# AT32UC3B1512 device description
Architecture: AVR32_UC3; Family: AVR UC3
Registers are 32-bit, read-write, reset 0x0 unless marked. A register's access mark holds for its fields unless they carry their own. Offsets are from the block's base; [hi:lo] are bit positions; {n}, {i} and the like mark numbered series.

## USART — Universal Synchronous/Asynchronous Receiver/Transmitter
Instances: USART0 0xffff1400, USART1 0xffff1800, USART2 0xffff1c00
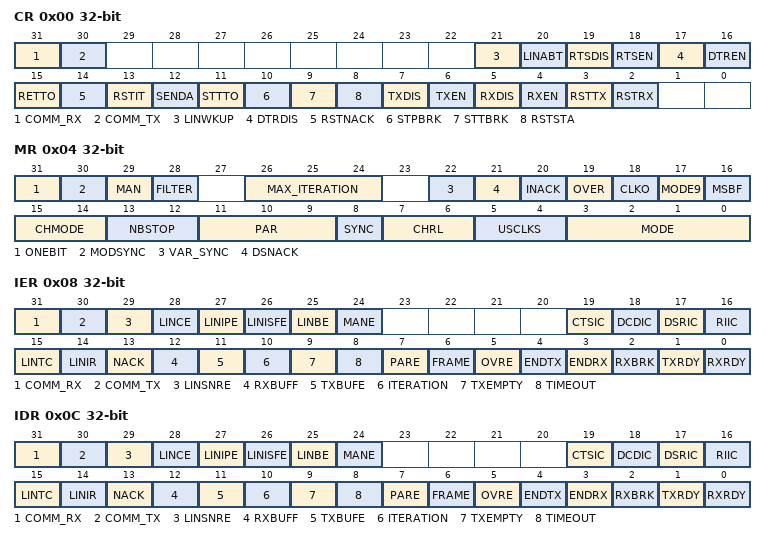
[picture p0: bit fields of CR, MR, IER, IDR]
0x00 CR wo reset not defined — Control Register
  [31] COMM_RX — Disable COMM_RX (from ARM) Interrupt
  [30] COMM_TX — Disable COMM_TX (from ARM) Interrupt
  [21] LINWKUP — Sends a wakeup signal on the LIN bus
  [20] LINABT — Abort the current LIN transmission
  [19] RTSDIS — Request to Send Disable
  [18] RTSEN — Request to Send Enable
  [17] DTRDIS — Data Terminal Ready Disable
  [16] DTREN — Data Terminal Ready Enable
  [15] RETTO — Rearm Time-out
  [14] RSTNACK — Reset Non Acknowledge
  [13] RSTIT — Reset Iterations
  [12] SENDA — Send Address
  [11] STTTO — Start Time-out
  [10] STPBRK — Stop Break
  [9] STTBRK — Start Break
  [8] RSTSTA — Reset Status Bits
  [7] TXDIS — Transmitter Disable
  [6] TXEN — Transmitter Enable
  [5] RXDIS — Receiver Disable
  [4] RXEN — Receiver Enable
  [3] RSTTX — Reset Transmitter
  [2] RSTRX — Reset Receiver
0x04 MR — Mode Register
  [31] ONEBIT — Start Frame Delimiter selector
  [30] MODSYNC — Manchester Synchronization Mode
  [29] MAN — Manchester Encoder/Decoder Enable
  [28] FILTER — Infrared Receive Line Filter
  [26:24] MAX_ITERATION — Max interation
  [22] VAR_SYNC — Variable synchronization of command/data sync Start Frame Delimiter
  [21] DSNACK — Disable Successive NACK
  [20] INACK — Inhibit Non Acknowledge
  [19] OVER — Oversampling Mode
    0=X16; 1=X8
  [18] CLKO — Clock Output Select
  [17] MODE9 — 9-bit Character Length
  [16] MSBF — Bit Order
    0=LSBF; 1=MSBF
  [15:14] CHMODE — Channel Mode
    0=NORMAL; 1=ECHO; 2=LOCAL_LOOP; 3=REMOTE_LOOP
  [13:12] NBSTOP — Number of Stop Bits
    0=1; 1=1_5; 2=2
  [11:9] PAR — Parity Type
    0=EVEN; 1=ODD; 2=SPACE; 3=MARK; 4=NONE; 6=MULTI
  [8] SYNC — Synchronous Mode Select
  [7:6] CHRL — Character Length.
    {v}={v+5} (v=0..3)
  [5:4] USCLKS — Clock Selection
    0=MCK; 1=MCK_DIV; 3=SCK
  [3:0] MODE — Usart Mode
    0=NORMAL; 1=RS485; 2=HARDWARE; 3=MODEM; 4=ISO7816_T0; 6=ISO7816_T1; 8=IRDA; 10=LIN_Master; 11=LIN_Slave; 14=SPI_Master; 15=SPI_Slave
0x08 IER wo — Interrupt Enable Register
  [31] COMM_RX — Enable COMM_RX (from ARM) Interrupt
  [30] COMM_TX — Enable COMM_TX (from ARM) Interrupt
  [29] LINSNRE — LIN Slave Not Responding Error Interrupt Enable
  [28] LINCE — LIN Checksum Error Interrupt Enable
  [27] LINIPE — LIN Identifier Parity Interrupt Enable
  [26] LINISFE — LIN Inconsistent Synch Field Error Interrupt Enable
  [25] LINBE — LIN Bus Error Interrupt Enable
  [24] MANE — Manchester Error Interrupt Enable
  [19] CTSIC — Clear to Send Input Change Interrupt Enable
  [18] DCDIC — Data Carrier Detect Input Change Interrupt Enable
  [17] DSRIC — Data Set Ready Input Change Enable
  [16] RIIC — Ring Indicator Input Change Enable
  [15] LINTC — LIN Transfer Conpleted Interrupt Enable
  [14] LINIR — LIN Identifier Received Interrupt Enable
  [13] NACK — Non Acknowledge Interrupt Enable
  [12] RXBUFF — Buffer Full Interrupt Enable
  [11] TXBUFE — Buffer Empty Interrupt Enable
  [10] ITERATION — Iteration Interrupt Enable
  [9] TXEMPTY — Transmitter Empty Interrupt Enable
  [8] TIMEOUT — Time-out Interrupt Enable
  [7] PARE — Parity Error Interrupt Enable
  [6] FRAME — Framing Error Interrupt Enable
  [5] OVRE — Overrun Error Interrupt Enable
  [4] ENDTX — End of Transmit Interrupt Enable
  [3] ENDRX — End of Receive Transfer Interrupt Enable
  [2] RXBRK — Receiver Break Interrupt Enable
  [1] TXRDY — Transmitter Ready Interrupt Enable
  [0] RXRDY — Receiver Ready Interrupt Enable
0x0C IDR wo — Interrupt Disable Register
  [31] COMM_RX — Disable COMM_RX (from ARM) Interrupt
  [30] COMM_TX — Disable COMM_TX (from ARM) Interrupt
  [29] LINSNRE — LIN Slave Not Responding Error Interrupt Disable
  [28] LINCE — LIN Checksum Error Interrupt Disable
  [27] LINIPE — LIN Identifier Parity Interrupt Disable
  [26] LINISFE — LIN Inconsistent Synch Field Error Interrupt Disable
  [25] LINBE — LIN Bus Error Interrupt Disable
  [24] MANE — Manchester Error Interrupt Disable
  [19] CTSIC — Clear to Send Input Change Interrupt Disable
  [18] DCDIC — Data Carrier Detect Input Change Interrupt Disable
  [17] DSRIC — Data Set Ready Input Change Disable
  [16] RIIC — Ring Indicator Input Change Disable
  [15] LINTC — LIN Transfer Conpleted Interrupt Disable
  [14] LINIR — LIN Identifier Received Interrupt Disable
  [13] NACK — Non Acknowledge Interrupt Disable
  [12] RXBUFF — Buffer Full Interrupt Disable
  [11] TXBUFE — Buffer Empty Interrupt Disable
  [10] ITERATION — Iteration Interrupt Disable
  [9] TXEMPTY — Transmitter Empty Interrupt Disable
  [8] TIMEOUT — Time-out Interrupt Disable
  [7] PARE — Parity Error Interrupt Disable
  [6] FRAME — Framing Error Interrupt Disable
  [5] OVRE — Overrun Error Interrupt Disable
  [4] ENDTX — End of Transmit Interrupt Disable
  [3] ENDRX — End of Receive Transfer Interrupt Disable
  [2] RXBRK — Receiver Break Interrupt Disable
  [1] TXRDY — Transmitter Ready Interrupt Disable
  [0] RXRDY — Receiver Ready Interrupt Disable
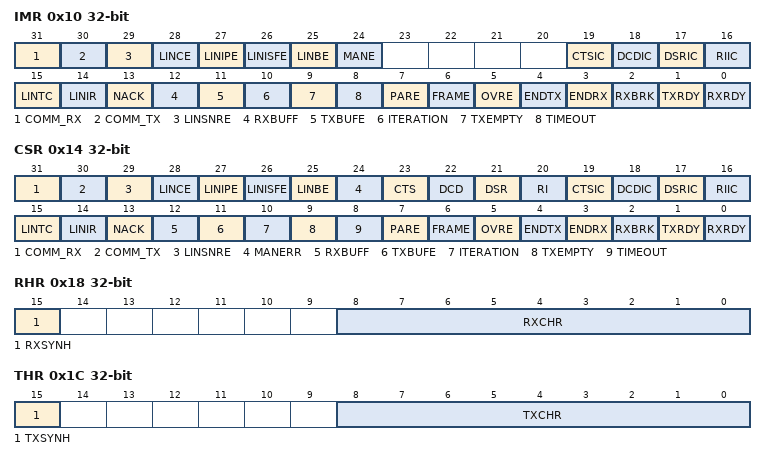
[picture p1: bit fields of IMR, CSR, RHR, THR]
0x10 IMR ro — Interrupt Mask Register
  [31] COMM_RX — Mask COMM_RX (from ARM) Interrupt
  [30] COMM_TX — Mask COMM_TX (from ARM) Interrupt
  [29] LINSNRE — LIN Slave Not Responding Error Interrupt Mask
  [28] LINCE — LIN Checksum Error Interrupt Mask
  [27] LINIPE — LIN Identifier Parity Interrupt Mask
  [26] LINISFE — LIN Inconsistent Synch Field Error Interrupt Mask
  [25] LINBE — LIN Bus Error Interrupt Mask
  [24] MANE — Manchester Error Interrupt Mask
  [19] CTSIC — Clear to Send Input Change Interrupt Mask
  [18] DCDIC — Data Carrier Detect Input Change Interrupt Mask
  [17] DSRIC — Data Set Ready Input Change Mask
  [16] RIIC — Ring Indicator Input Change Mask
  [15] LINTC — LIN Transfer Conpleted Interrupt Mask
  [14] LINIR — LIN Identifier Received Interrupt Mask
  [13] NACK — Non Acknowledge Interrupt Mask
  [12] RXBUFF — Buffer Full Interrupt Mask
  [11] TXBUFE — Buffer Empty Interrupt Mask
  [10] ITERATION — Iteration Interrupt Mask
  [9] TXEMPTY — TXEMPTY Interrupt Mask
  [8] TIMEOUT — Time-out Interrupt Mask
  [7] PARE — Parity Error Interrupt Mask
  [6] FRAME — Framing Error Interrupt Mask
  [5] OVRE — Overrun Error Interrupt Mask
  [4] ENDTX — End of Transmit Interrupt Mask
  [3] ENDRX — End of Receive Transfer Interrupt Mask
  [2] RXBRK — Receiver Break Interrupt Mask
  [1] TXRDY — TXRDY Interrupt Mask
  [0] RXRDY — RXRDY Interrupt Mask
0x14 CSR ro — Channel Status Register
  [31] COMM_RX — COMM_RX: (from ARM)
  [30] COMM_TX — COMM_TX: (from ARM)
  [29] LINSNRE — LIN Slave Not Responding Error
  [28] LINCE — LIN Checksum Error
  [27] LINIPE — LIN Identifier Parity Error
  [26] LINISFE — LIN Inconsistent Synch Field Error
  [25] LINBE — LIN Bit Error
  [24] MANERR — Manchester Error
  [23] CTS — Image of CTS Input
  [22] DCD — Image of DCD Input
  [21] DSR — Image of DSR Input
  [20] RI — Image of RI Input
  [19] CTSIC — Clear to Send Input Change Flag
  [18] DCDIC — Data Carrier Detect Input Change Flag
  [17] DSRIC — Data Set Ready Input Change Flag
  [16] RIIC — Ring Indicator Input Change Flag
  [15] LINTC — LIN Transfer Conpleted
  [14] LINIR — LIN Identifier Received
  [13] NACK — Non Acknowledge
  [12] RXBUFF — Reception Buffer Full
  [11] TXBUFE — Transmission Buffer Empty
  [10] ITERATION — Max number of Repetitions Reached
  [9] TXEMPTY — Transmitter Empty
  [8] TIMEOUT — Receiver Time-out
  [7] PARE — Parity Error
  [6] FRAME — Framing Error
  [5] OVRE — Overrun Error
  [4] ENDTX — End of Transmitter Transfer
  [3] ENDRX — End of Receiver Transfer
  [2] RXBRK — Break Received/End of Break
  [1] TXRDY — Transmitter Ready
  [0] RXRDY — Receiver Ready
0x18 RHR ro — Receiver Holding Register
  [15] RXSYNH — Received Sync
  [8:0] RXCHR — Received Character
0x1C THR wo reset not defined — Transmitter Holding Register
  [15] TXSYNH — Sync Field to be transmitted
  [8:0] TXCHR — Character to be Transmitted
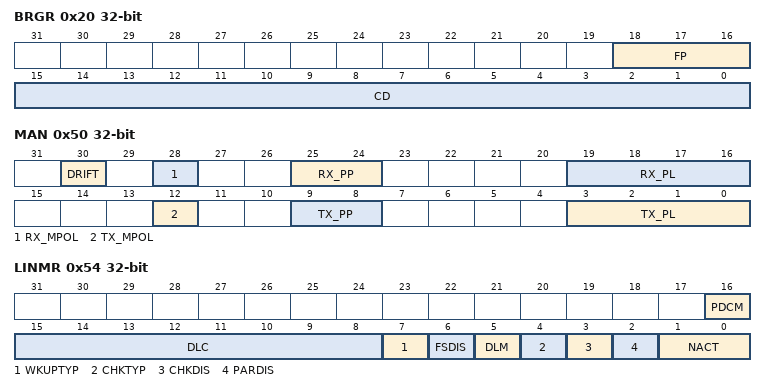
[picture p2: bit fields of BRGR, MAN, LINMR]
0x20 BRGR — Baud Rate Generator Register
  [18:16] FP — Fractional Part
  [15:0] CD — Clock Divisor
    0=DISABLE; 1=BYPASS
0x24 RTOR — Receiver Time-out Register
  [15:0] TO — Time-out Value
    0=DISABLE
0x28 TTGR — Transmitter Timeguard Register
  [7:0] TG — Timeguard Value
    0=DISABLE
0x40 FIDI reset 0x174 — FI DI Ratio Register
  [10:0] FI_DI_RATIO — FI Over DI Ratio Value
    0=DISABLE
0x44 NER ro reset not defined — Number of Errors Register
  [7:0] NB_ERRORS — Error number during ISO7816 transfers
0x4C IFR — IrDA Filter Register
  [7:0] IRDA_FILTER
0x50 MAN reset not defined — Manchester Configuration Register
  [30] DRIFT — Drift compensation
  [28] RX_MPOL — Receiver Manchester Polarity
  [25:24] RX_PP — Receiver Preamble Pattern detected
  [19:16] RX_PL — Receiver Preamble Length
  [12] TX_MPOL — Transmitter Manchester Polarity
  [9:8] TX_PP — Transmitter Preamble Pattern
  [3:0] TX_PL — Transmitter Preamble Length
0x54 LINMR — LIN Mode Register
  [16] PDCM — PDC Mode
  [15:8] DLC — Data Length Control
  [7] WKUPTYP — Wakeup Signal Type
  [6] FSDIS — Frame Slot Mode Disable
  [5] DLM — Data Length Mode
  [4] CHKTYP — Checksum Type
  [3] CHKDIS — Checksum Disable
  [2] PARDIS — Parity Disable
  [1:0] NACT — LIN Node Action
    0=PUBLISH; 1=SUBSCRIBE; 2=IGNORE
0x58 LINIR — LIN Identifier Register
  [7:0] IDCHR — Identifier Character
0xFC VERSION ro reset 0x400
